# M0A21 register map
File version: 1.0
Registers are 32-bit, read-write, reset 0x0 unless marked. A register's access mark holds for its fields unless they carry their own. Offsets are from the block's base; [hi:lo] are bit positions; {n}, {i} and the like mark numbered series.

## CLK — CLK Register Map
Base 0x40000200
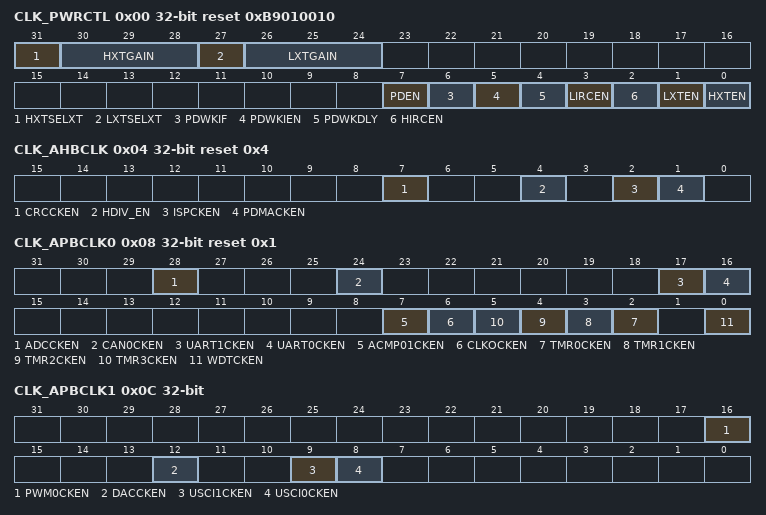
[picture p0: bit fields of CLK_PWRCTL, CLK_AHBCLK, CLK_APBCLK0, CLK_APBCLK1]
0x00 CLK_PWRCTL reset 0xB9010010 (reset mask 0xFFFFFFF0) — System Power-down Control Register
  [31] HXTSELXT — HXT Crystal Mode Selection. Note 2: This bit is write protected. Refer to the SYS_REGLCTL register.
    0=HXT works as external clock mode. PA.5 is configured as external clock input pin; 1=HXT works as crystal mode. PA.4 and PA.5 are configured as high speed crystal (HXT) pins
  [30:28] HXTGAIN — HXT Gain Control Bit (Write Protect). Please refer to HXT Charateristic. Note: This bit is write protected. Refer to the SYS_REGLCTL register.
  [27] LXTSELXT — LXT Crystal Mode Selection. Note 2: This bit is write protected. Refer to the SYS_REGLCTL register.
    0=LXT works as external clock mode. PC.5 is configured as external clock input pin; 1=LXT works as crystal mode. PC.4 and PC.5 are configured as low speed crystal (LXT) pins
  [26:24] LXTGAIN — LXT Gain Control Bit (Write Protect). Please refer to LXT Charateristic. Note: This bit is write protected. Refer to the SYS_REGLCTL register.
  [7] PDEN — System Power-down Enable (Write Protect). When this bit is set to 1, Power-down mode is enabled and chip keeps active utill the CPU sleep mode is also active and then the chip enters Power-down mode. When chip wakes up from Power-down mode, this bit is auto cleared. Users need to set this bit again for next Power-down. In Power-down mode, HXT and the HIRC will be disabled in this mode, but LXT and LIRC are not controlled by Power-down mode. If user disable LIRC before entering power-down mode, this bit should be set after LIRC disabled 50us. In Power-down mode, system clock are disabled, and ignored the clock source selection. The clocks of peripheral are not controlled by Power-down mode, if the peripheral clock source is from LXT or LIRC. Note: This bit is write protected. Refer to the SYS_REGLCTL register.
    0=Chip operating normally or chip in idle mode because of WFI command; 1=Chip enters Power-down mode instant or wait CPU sleep command WFI
  [6] PDWKIF — Power-down Mode Wake-up Interrupt Status. Set by 'Power-down wake-up event', it indicates that resume from Power-down mode' The flag is set if any wake-up source is occurred. Refer Power Modes and Wake-up Sources chapter. Note 1: Write 1 to clear the bit to 0. Note 2: This bit works only if PDWKIEN (CLK_PWRCTL[5]) set to 1.
  [5] PDWKIEN — Power-down Mode Wake-up Interrupt Enable Bit (Write Protect). Note 1: The interrupt will occur when both PDWKIF and PDWKIEN are high. Note 2: This bit is write protected. Refer to the SYS_REGLCTL register.
    0=Power-down mode wake-up interrupt Disabled; 1=Power-down mode wake-up interrupt Enabled
  [4] PDWKDLY — Enable the Wake-up Delay Counter (Write Protect). When the chip wakes up from Power-down mode, the clock control will delay certain clock cycles to wait system clock stable. The delayed clock cycle is 4096 clock cycles when chip works at external high speed crystal oscillator (HXT), and 512 clock cycles when chip works at internal high speed RC oscillator (HIRC). Note: This bit is write protected. Refer to the SYS_REGLCTL register.
    0=Clock cycles delay Disabled; 1=Clock cycles delay Enabled
  [3] LIRCEN — LIRC Enable Bit (Write Protect). Note: This bit is write protected. Refer to the SYS_REGLCTL register.
    0=Internal low speed RC oscillator (LIRC) Disabled; 1=Internal low speed RC oscillator (LIRC) Enabled
  [2] HIRCEN — HIRC Enable Bit (Write Protect). Note: This bit is write protected. Refer to the SYS_REGLCTL register.
    0=Internal high speed RC oscillator (HIRC) Disabled; 1=Internal high speed RC oscillator (HIRC) Enabled
  [1] LXTEN — LXT Enable Bit (Write Protect). Note 1: Reset by power on reset. Note 2: This bit is write protected. Refer to the SYS_REGLCTL register.
    0=External low speed crystal (LXT) Disabled; 1=External low speed crystal (LXT) Enabled
  [0] HXTEN — HXT Enable Bit (Write Protect). Note 1: Reset by power on reset. Note 2: This bit is write protected. Refer to the SYS_REGLCTL register.
    0=Eexternal high speed crystal (HXT) Disabled; 1=External high speed crystal (HXT) Enabled
0x04 CLK_AHBCLK reset 0x4 — AHB Devices Clock Enable Control Register
  [7] CRCCKEN — CRC Generator Controller Clock Enable Bit
    0=CRC peripheral clock Disabled; 1=CRC peripheral clock Enabled
  [4] HDIV_EN — Divider Controller Clock Enable Control
    0=Divider controller peripheral clock Disabled; 1=Divider controller peripheral clock Enabled
  [2] ISPCKEN — Flash ISP Controller Clock Enable Bit
    0=Flash ISP peripheral clock Disabled; 1=Flash ISP peripheral clock Enabled
  [1] PDMACKEN — PDMA Controller Clock Enable Bit
    0=PDMA peripheral clock Disabled; 1=PDMA peripheral clock Enabled
0x08 CLK_APBCLK0 reset 0x1 — APB Devices Clock Enable Control Register 0
  [28] ADCCKEN — Analog-digital-converter Clock Enable Bit
    0=ADC clock Disabled; 1=ADC clock Enabled
  [24] CAN0CKEN — CAN0 Clock Enable Bit
    0=CAN0 clock Disabled; 1=CAN0 clock Enabled
  [17] UART1CKEN — UART1 Clock Enable Bit
    0=UART1 clock Disabled; 1=UART1 clock Enabled
  [16] UART0CKEN — UART0 Clock Enable Bit
    0=UART0 clock Disabled; 1=UART0 clock Enabled
  [7] ACMP01CKEN — Analog Comparator 0/1 Clock Enable Bit
    0=Analog comparator 0/1 clock Disabled; 1=Analog comparator 0/1 clock Enabled
  [6] CLKOCKEN — CLKO Clock Enable Bit
    0=CLKO clock Disabled; 1=CLKO clock Enabled
  [n+2] TMR{n}CKEN (n=0..3) — Timer{n} Clock Enable Bit
    0=Timer{n} clock Disabled; 1=Timer{n} clock Enabled
  [0] WDTCKEN — Watchdog Timer Clock Enable Bit (Write Protect). Note 1: This bit is write protected. Refer to the SYS_REGLCTL register. Note 2: This bit is reset by power on reset, Watchdog reset or software chip reset.
    0=Watchdog timer clock Disabled; 1=Watchdog timer clock Enabled
0x0C CLK_APBCLK1 — APB Devices Clock Enable Control Register 1
  [16] PWM0CKEN — PWM0 Clock Enable Bit
    0=PWM0 clock Disabled; 1=PWM0 clock Enabled
  [12] DACCKEN — DAC Clock Enable Bit
    0=DAC clock Disabled; 1=DAC clock Enabled
  [9] USCI1CKEN — USCI1 Clock Enable Bit
    0=USCI1 clock Disabled; 1=USCI1 clock Enabled
  [8] USCI0CKEN — USCI0 Clock Enable Bit
    0=USCI0 clock Disabled; 1=USCI0 clock Enabled
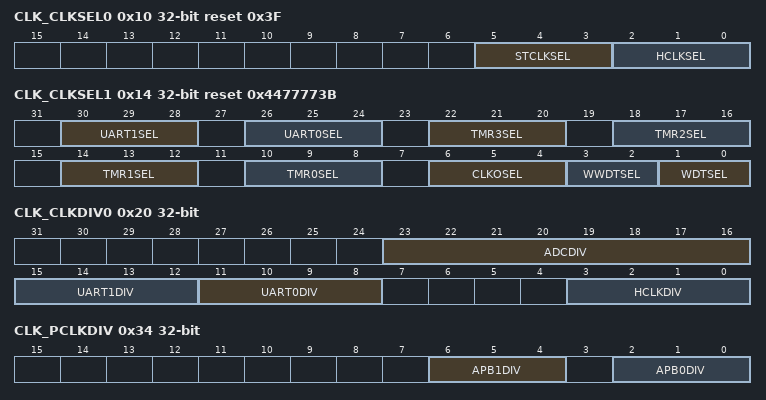
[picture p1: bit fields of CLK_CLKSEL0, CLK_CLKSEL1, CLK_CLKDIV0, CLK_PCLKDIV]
0x10 CLK_CLKSEL0 reset 0x3F — Clock Source Select Control Register 0
  [5:3] STCLKSEL — Cortex-M0 SysTick Clock Source Selection (Write Protect). Note 2: This bit is write protected. Refer to the SYS_REGLCTL register.
    0=Clock source from HXT; 1=Clock source from LXT; 2=Clock source from HXT/2; 3=Clock source from HCLK/2; 7=Clock source from HIRC/2
  [2:0] HCLKSEL — HCLK Clock Source Selection (Write Protect). Before clock switching, the related clock sources (both pre-select and new-select) must be turned on. Note 1: This bit is write protected. Refer to the SYS_REGLCTL register. Note 2: Reset by power on reset
    0=Clock source from HXT; 1=Clock source from LXT; 3=Clock source from LIRC; 7=Clock source from HIRC
0x14 CLK_CLKSEL1 reset 0x4477773B — Clock Source Select Control Register 1
  [30:28] UART1SEL — UART1 Clock Source Selection
    0=Clock source from external high speed crystal oscillator (HXT); 2=Clock source from external low speed crystal oscillator (LXT); 3=Clock source from internal high speed RC oscillator (HIRC); 4=Clock source from PCLK1; 5=Clock source from internal low speed RC oscillator (LIRC)
  [26:24] UART0SEL — UART0 Clock Source Selection
    0=Clock source from external high speed crystal oscillator (HXT); 2=Clock source from external low speed crystal oscillator (LXT); 3=Clock source from internal high speed RC oscillator (HIRC); 4=Clock source from PCLK0; 5=Clock source from internal low speed RC oscillator (LIRC)
  [22:20] TMR3SEL — TIMER3 Clock Source Selection
    0=Clock source from external high speed crystal oscillator (HXT); 1=Clock source from external low speed crystal oscillator (LXT); 2=Clock source from PCLK1; 3=Clock source from external clock T3 pin; 5=Clock source from internal low speed RC oscillator (LIRC); 7=Clock source from internal high speed RC oscillator (HIRC)
  [18:16] TMR2SEL — TIMER2 Clock Source Selection
    0=Clock source from external high speed crystal oscillator (HXT); 1=Clock source from external low speed crystal oscillator (LXT); 2=Clock source from PCLK1; 3=Clock source from external clock T2 pin; 5=Clock source from internal low speed RC oscillator (LIRC); 7=Clock source from internal high speed RC oscillator (HIRC)
  [14:12] TMR1SEL — TIMER1 Clock Source Selection
    0=Clock source from external high speed crystal oscillator (HXT); 1=Clock source from external low speed crystal oscillator (LXT); 2=Clock source from PCLK0; 3=Clock source from external clock T1 pin; 5=Clock source from internal low speed RC oscillator (LIRC); 7=Clock source from internal high speed RC oscillator (HIRC)
  [10:8] TMR0SEL — TIMER0 Clock Source Selection
    0=Clock source from external high speed crystal oscillator (HXT); 1=Clock source from external low speed crystal oscillator (LXT); 2=Clock source from PCLK0; 3=Clock source from external clock T0 pin; 5=Clock source from internal low speed RC oscillator (LIRC); 7=Clock source from internal high speed RC oscillator (HIRC)
  [6:4] CLKOSEL — Clock Divider Clock Source Selection
    0=Clock source from external high speed crystal oscillator (HXT); 1=Clock source from external low speed crystal oscillator (LXT); 2=Clock source from HCLK; 4=Clock source from internal low speed RC oscillator (LIRC); 5=Clock source from internal high speed RC oscillator (HIRC)
  [3:2] WWDTSEL — Window Watchdog Timer Clock Source Selection (Write Protect)
    2=Clock source from HCLK/2048; 3=Clock source from internal low speed RC oscillator (LIRC)
  [1:0] WDTSEL — Watchdog Timer Clock Source Selection (Write Protect). Note: This bit is write protected. Refer to the SYS_REGLCTL register. 2. It will be forced to 11 when CONFIG0[31], CONFIG0[4], CONFIG0[3] are all ones.
    1=Clock source from external low speed crystal oscillator (LXT); 2=Clock source from HCLK/2048; 3=Clock source from internal low speed RC oscillator (LIRC)
0x18 CLK_CLKSEL2 reset 0x20032B — Clock Source Select Control Register 2
  [21:20] ADCSEL — ADC Clock Source Selection
    0=Clock source from external high speed crystal oscillator (HXT) clock; 2=Clock source from PCLK1; 3=Clock source from internal high speed RC oscillator (HIRC) clock
0x20 CLK_CLKDIV0 — Clock Divider Number Register 0
  [23:16] ADCDIV — ADC Clock Divide Number From ADC Clock Source
  [15:12] UART1DIV — UART1 Clock Divide Number From UART1 Clock Source
  [11:8] UART0DIV — UART0 Clock Divide Number From UART0 Clock Source
  [3:0] HCLKDIV — HCLK Clock Divide Number From HCLK Clock Source
0x34 CLK_PCLKDIV — APB Clock Divider Register
  [6:4] APB1DIV — APB1 Clock DIvider. APB1 clock can be divided from HCLK. Others: Reserved.
  [2:0] APB0DIV — APB0 Clock DIvider. APB0 clock can be divided from HCLK. Others: Reserved.
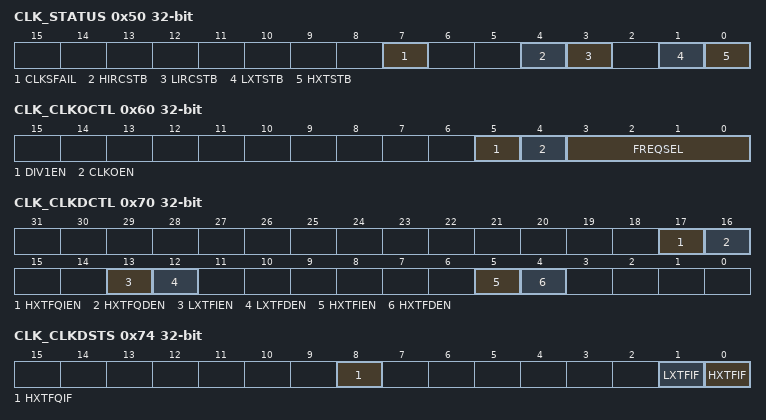
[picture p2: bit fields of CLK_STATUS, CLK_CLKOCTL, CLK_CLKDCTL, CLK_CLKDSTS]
0x50 CLK_STATUS ro (reset mask 0xFFFFFF00) — Clock Status Monitor Register
  [7] CLKSFAIL — Clock Switching Fail Flag (Read Only). This bit is updated when software switches system clock source. If switch target clock is stable, this bit will be set to 0. If switch target clock is not stable, this bit will be set to 1. Note: Write 1 to clear the bit to 0.
    0=Clock switching success; 1=Clock switching failure
  [4] HIRCSTB — HIRC Clock Source Stable Flag (Read Only)
    0=Internal high speed RC oscillator (HIRC) clock is not stable or disabled; 1=Internal high speed RC oscillator (HIRC) clock is stable and enabled
  [3] LIRCSTB — LIRC Clock Source Stable Flag (Read Only)
    0=Internal low speed RC oscillator (LIRC) clock is not stable or disabled; 1=Internal low speed RC oscillator (LIRC) clock is stable and enabled
  [1] LXTSTB — LXT Clock Source Stable Flag (Read Only)
    0=External low speed crystal oscillator (LXT) clock is not stable or disabled; 1=External low speed crystal oscillator (LXT) clock is stabled and enabled
  [0] HXTSTB — HXT Clock Source Stable Flag (Read Only)
    0=External high speed crystal oscillator (HXT) clock is not stable or disabled; 1=External high speed crystal oscillator (HXT) clock is stable and enabled
0x60 CLK_CLKOCTL — Clock Output Control Register
  [5] DIV1EN — Clock Output Divide One Enable Bit
    0=Clock Output will output clock with source frequency divided by FREQSEL; 1=Clock Output will output clock with source frequency
  [4] CLKOEN — Clock Output Enable Bit
    0=Clock Output function Disabled; 1=Clock Output function Enabled
  [3:0] FREQSEL — Clock Output Frequency Selection. The formula of output frequency is. Fin is the input clock frequency. Fout is the frequency of divider output clock. N is the 4-bit value of FREQSEL[3:0].
0x70 CLK_CLKDCTL — Clock Fail Detector Control Register
  [17] HXTFQIEN — HXT Clock Frequency Range Detector Interrupt Enable Bit
    0=External high speed crystal oscillator (HXT) clock frequency range detector fail interrupt Disabled; 1=External high speed crystal oscillator (HXT) clock frequency range detector fail interrupt Enabled
  [16] HXTFQDEN — HXT Clock Frequency Range Detector Enable Bit
    0=External high speed crystal oscillator (HXT) clock frequency range detector Disabled; 1=External high speed crystal oscillator (HXT) clock frequency range detector Enabled
  [13] LXTFIEN — LXT Clock Fail Interrupt Enable Bit
    0=External low speed crystal oscillator (LXT) clock fail interrupt Disabled; 1=External low speed crystal oscillator (LXT) clock fail interrupt Enabled
  [12] LXTFDEN — LXT Clock Fail Detector Enable Bit
    0=External low speed crystal oscillator (LXT) clock fail detector Disabled; 1=External low speed crystal oscillator (LXT) clock fail detector Enabled
  [5] HXTFIEN — HXT Clock Fail Interrupt Enable Bit
    0=External high speed crystal oscillator (HXT) clock fail interrupt Disabled; 1=External high speed crystal oscillator (HXT) clock fail interrupt Enabled
  [4] HXTFDEN — HXT Clock Fail Detector Enable Bit
    0=External high speed crystal oscillator (HXT) clock fail detector Disabled; 1=External high speed crystal oscillator (HXT) clock fail detector Enabled
0x74 CLK_CLKDSTS — Clock Fail Detector Status Register
  [8] HXTFQIF — HXT Clock Frequency Range Detector Interrupt Flag (Write Protect). Note: Write 1 to clear the bit to 0.
    0=External high speed crystal oscillator (HXT) clock frequency is normal; 1=External high speed crystal oscillator (HXT) clock frequency is abnormal
  [1] LXTFIF — LXT Clock Fail Interrupt Flag (Write Protect). Note: Write 1 to clear the bit to 0.
    0=External low speed crystal oscillator (LXT) clock is normal; 1=External low speed crystal oscillator (LXT) stops
  [0] HXTFIF — HXT Clock Fail Interrupt Flag (Write Protect). Note: Write 1 to clear the bit to 0.
    0=External high speed crystal oscillator (HXT) clock is normal; 1=External high speed crystal oscillator (HXT) clock stops
0x78 CLK_CDUPB — Clock Frequency Range Detector Upper Boundary Register
  [9:0] UPERBD — HXT Clock Frequency Range Detector Upper Boundary Value. The bits define the maximum value of frequency range detector window. When HXT frequency is higher than this maximum frequency value, the HXT Clock Frequency Range Detector Interrupt Flag will be set to 1.
0x7C CLK_CDLOWB — Clock Frequency Range Detector Lower Boundary Register
  [9:0] LOWERBD — HXT Clock Frequency Range Detector Lower Boundary Value. The bits define the minimum value of frequency range detector window. When HXT frequency is lower than this minimum frequency value, the HXT Clock Frequency Range Detector Interrupt Flag will be set to 1.
0xB4 CLK_HXTFSEL — HXT Filter Select Control Register
  [0] HXTFSEL — HXT Filter Select. Note: This bit should not be changed during HXT running.
    0=HXT frequency is greater than12 MHz; 1=HXT frequency is less than or equal to 12 MHz
